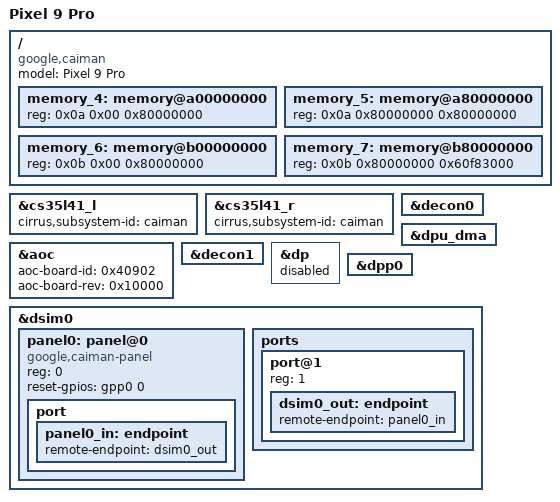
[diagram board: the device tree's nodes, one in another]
// SPDX-License-Identifier: GPL-2.0-only
/*
 * Pixel 9 Pro (caiman) Device Tree
 *
 * Copyright 2025 Trijal Saha - <trijalsaha2012@gmail.com>
 */

/dts-v1/;

#include "zumapro-pixel-common.dtsi"
#include "zumapro-caimito-bcm4390.dtsi"
#include "zumapro-caimito-s5400.dtsi"
#include "zumapro-caimito-cs35l41.dtsi"

/ {
	model = "Pixel 9 Pro";
	compatible = "google,caiman", "google,zumapro-caiman", "google,zumapro";

	memory_4: memory@a00000000 {
		device_type = "memory";
		reg = <0x0a 0x00 0x80000000>;
	};

	memory_5: memory@a80000000 {
		device_type = "memory";
		reg = <0x0a 0x80000000 0x80000000>;
	};

	memory_6: memory@b00000000 {
		device_type = "memory";
		reg = <0x0b 0x00 0x80000000>;
	};

	memory_7: memory@b80000000 {
		device_type = "memory";
		reg = <0x0b 0x80000000 0x60f83000>;
	};
};

/* Board identity the AOC firmware reads at boot. */
/*
 * The Halo DSP speaker-protection tuning is specific to this board's drivers
 * and to each channel, so the firmware has to be named for both.  This is what
 * wm_adsp interpolates as the system name: the amplifiers ask for
 * cirrus/cs35l41-dsp1-spk-prot-caiman.wmfw, and for a tuning of the same stem
 * with "-r" appended on the right-hand amplifier, which carries the prefix.
 */
&cs35l41_l {
	cirrus,subsystem-id = "caiman";
};

&cs35l41_r {
	cirrus,subsystem-id = "caiman";
};

&aoc {
	aoc-board-id = <0x40902>;
	aoc-board-rev = <0x10000>;
};

// &decon_autorefresh_bit {
// 	status = "okay";
// };
//
// &cont_splash_mem {
// 	// reg = <0x0 0xfac00000 (1440 * 3120 * 4)>;
// 	reg = <0x0 0xfac00000 (1280 * 2856 * 4)>;
//
// 	status = "okay";
// };
//
// &framebuffer0 {
// 	// width = <1440>;
// 	// height = <3120>;
// 	// stride = <(1440 * 4)>;
// 	width = <1280>;
// 	height = <2856>;
// 	stride = <(1280 * 4)>;
// 	format = "a8r8g8b8";
//
// 	status = "okay";
// };

/*
 * Display (DPU) bring-up for caiman.
 *
 * The DECON0/DPP/DPU-DMA/DSIM0 topology is defined in zumapro.dtsi; this
 * board section enables it and attaches the caiman (google,gs-km4) panel via
 * a minimal boot-handoff panel driver (google,caiman-panel).
 *
 * The bootloader initialises the DCPHY, DSIM link and panel and leaves the
 * (dual-DSC, command-mode) link streaming - that is what the simple-
 * framebuffer splash draws into. The DECON DRM stack takes over scanning its
 * own framebuffer into that running link (the DECON emits the matching
 * dual-DSC stream). Disable the simple-framebuffer (and the decon-autorefresh
 * mmio-init) before relying on the DECON output, since enabling decon0 runs
 * decon_reset() and tears the bootloader splash down.
 */
&decon0 {
	status = "okay";
};

&dpu_dma {
	status = "okay";
};

/*
 * DP alt mode output: DECON1 into the DP link. Enabling both at once reset
 * the SoC five times over, early enough that neither ramoops nor the journal
 * caught anything, so they come back one at a time.
 *
 * DECON1 first, with nothing attached to it: it comes up as a second CRTC
 * beside the live panel pipe and the two share the window and sub register
 * blocks, which is the half of the pair that can be tested without the DP
 * driver running at all. The DPOSC divider reads 39.936MHz, so the clock
 * definitions are sound, but nothing has enabled those gates yet.
 *
 * The DP node also still does not match its driver: it wants reg-names
 * "link_base" and "phy_base", and phy_base is the combo PHY range that
 * usbdrd31_phy owns. That has to be settled before it is enabled again.
 */
&decon1 {
	status = "okay";
};

&dp {
	status = "disabled";
};

&dpp0 {
	status = "okay";
};

&dsim0 {
	status = "okay";

	panel0: panel@0 {
		compatible = "google,caiman-panel";
		reg = <0>;
		/* DDIC reset for cold power-on (unused on boot handover) */
		reset-gpios = <&gpp0 0 GPIO_ACTIVE_HIGH>;

		port {
			panel0_in: endpoint {
				remote-endpoint = <&dsim0_out>;
			};
		};
	};

	ports {
		port@1 {
			reg = <1>;
			dsim0_out: endpoint {
				remote-endpoint = <&panel0_in>;
			};
		};
	};
};
